VERSION ""

NS_ :

BS_:

BU_: XXX

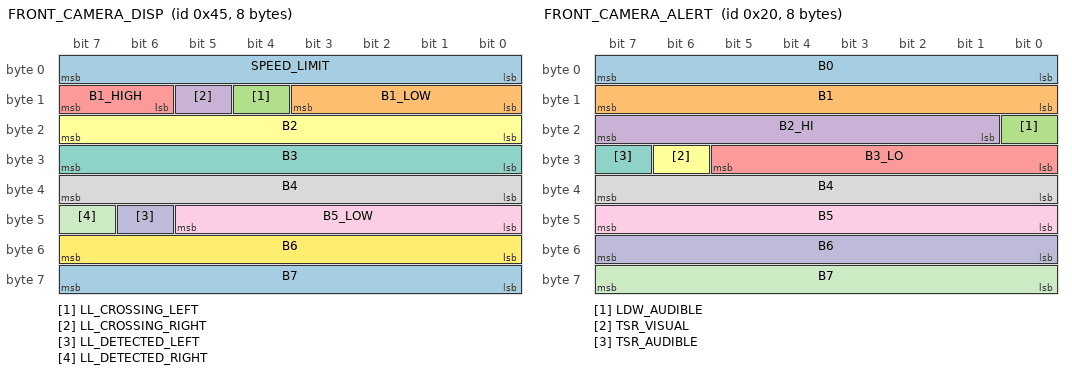
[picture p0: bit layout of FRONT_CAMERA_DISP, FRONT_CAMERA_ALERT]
BO_ 69 FRONT_CAMERA_DISP: 8 XXX
 SG_ SPEED_LIMIT : 0|8@1+ (1,0) [0|255] "mph" XXX
 SG_ B1_LOW : 8|4@1+ (1,0) [0|15] "" XXX
 SG_ LL_CROSSING_LEFT : 12|1@1+ (1,0) [0|1] "" XXX
 SG_ LL_CROSSING_RIGHT : 13|1@1+ (1,0) [0|1] "" XXX
 SG_ B1_HIGH : 14|2@1+ (1,0) [0|3] "" XXX
 SG_ B2 : 16|8@1+ (1,0) [0|255] "" XXX
 SG_ B3 : 24|8@1+ (1,0) [0|255] "" XXX
 SG_ B4 : 32|8@1+ (1,0) [0|255] "" XXX
 SG_ B5_LOW : 40|6@1+ (1,0) [0|63] "" XXX
 SG_ LL_DETECTED_LEFT : 46|1@1+ (1,0) [0|1] "" XXX
 SG_ LL_DETECTED_RIGHT : 47|1@1+ (1,0) [0|1] "" XXX
 SG_ B6 : 48|8@1+ (1,0) [0|255] "" XXX
 SG_ B7 : 56|8@1+ (1,0) [0|255] "" XXX

BO_ 32 FRONT_CAMERA_ALERT: 8 XXX
 SG_ B0 : 0|8@1+ (1,0) [0|255] "" XXX
 SG_ B1 : 8|8@1+ (1,0) [0|255] "" XXX
 SG_ LDW_AUDIBLE : 16|1@1+ (1,0) [0|1] "" XXX
 SG_ B2_HI : 17|7@1+ (1,0) [0|127] "" XXX
 SG_ B3_LO : 24|6@1+ (1,0) [0|63] "" XXX
 SG_ TSR_VISUAL : 30|1@1+ (1,0) [0|1] "" XXX
 SG_ TSR_AUDIBLE : 31|1@1+ (1,0) [0|1] "" XXX
 SG_ B4 : 32|8@1+ (1,0) [0|255] "" XXX
 SG_ B5 : 40|8@1+ (1,0) [0|255] "" XXX
 SG_ B6 : 48|8@1+ (1,0) [0|255] "" XXX
 SG_ B7 : 56|8@1+ (1,0) [0|255] "" XXX

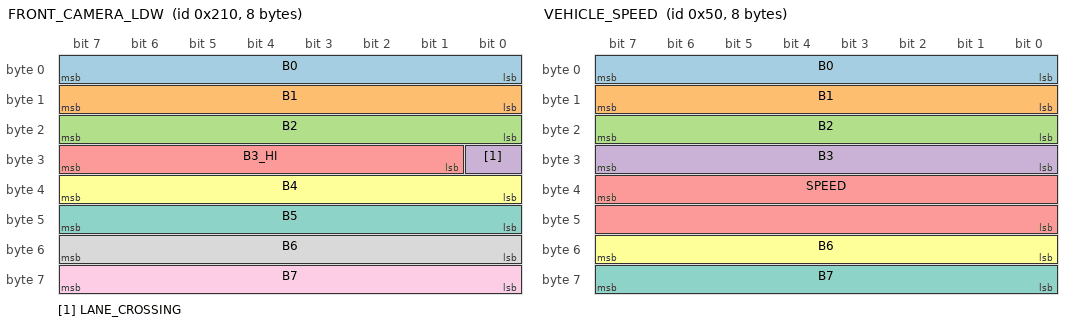
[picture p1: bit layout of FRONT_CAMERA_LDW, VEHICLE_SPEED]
BO_ 528 FRONT_CAMERA_LDW: 8 XXX
 SG_ B0 : 0|8@1+ (1,0) [0|255] "" XXX
 SG_ B1 : 8|8@1+ (1,0) [0|255] "" XXX
 SG_ B2 : 16|8@1+ (1,0) [0|255] "" XXX
 SG_ LANE_CROSSING : 24|1@1+ (1,0) [0|1] "" XXX
 SG_ B3_HI : 25|7@1+ (1,0) [0|127] "" XXX
 SG_ B4 : 32|8@1+ (1,0) [0|255] "" XXX
 SG_ B5 : 40|8@1+ (1,0) [0|255] "" XXX
 SG_ B6 : 48|8@1+ (1,0) [0|255] "" XXX
 SG_ B7 : 56|8@1+ (1,0) [0|255] "" XXX

BO_ 80 VEHICLE_SPEED: 8 XXX
 SG_ B0 : 0|8@1+ (1,0) [0|255] "" XXX
 SG_ B1 : 8|8@1+ (1,0) [0|255] "" XXX
 SG_ B2 : 16|8@1+ (1,0) [0|255] "" XXX
 SG_ B3 : 24|8@1+ (1,0) [0|255] "" XXX
 SG_ SPEED : 39|16@0+ (0.0140625,-460.8) [0|320] "kph" XXX
 SG_ B6 : 48|8@1+ (1,0) [0|255] "" XXX
 SG_ B7 : 56|8@1+ (1,0) [0|255] "" XXX

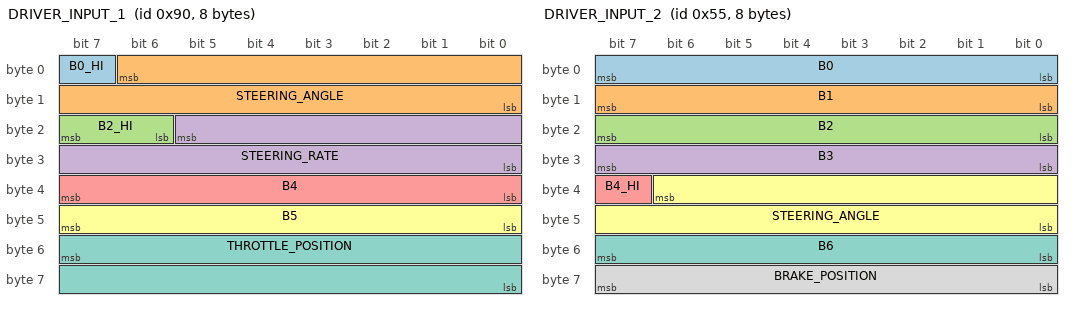
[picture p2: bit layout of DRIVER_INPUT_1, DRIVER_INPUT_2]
BO_ 144 DRIVER_INPUT_1: 8 XXX
 SG_ B0_HI : 7|1@1+ (1,0) [0|1] "" XXX
 SG_ STEERING_ANGLE : 6|15@0- (0.0625,0) [-1024|1024] "deg" XXX
 SG_ B2_HI : 22|2@1+ (1,0) [0|3] "" XXX
 SG_ STEERING_RATE : 21|14@0- (0.5,0) [-4096|4096] "deg/s" XXX
 SG_ B4 : 32|8@1+ (1,0) [0|255] "" XXX
 SG_ B5 : 40|8@1+ (1,0) [0|255] "" XXX
 SG_ THROTTLE_POSITION : 55|16@0+ (0.00390625,-128) [0|100] "%" XXX

BO_ 85 DRIVER_INPUT_2: 8 XXX
 SG_ B0 : 0|8@1+ (1,0) [0|255] "" XXX
 SG_ B1 : 8|8@1+ (1,0) [0|255] "" XXX
 SG_ B2 : 16|8@1+ (1,0) [0|255] "" XXX
 SG_ B3 : 24|8@1+ (1,0) [0|255] "" XXX
 SG_ B4_HI : 39|1@1+ (1,0) [0|1] "" XXX
 SG_ STEERING_ANGLE : 38|15@0- (0.0625,0) [-1024|1024] "deg" XXX
 SG_ B6 : 48|8@1+ (1,0) [0|255] "" XXX
 SG_ BRAKE_POSITION : 56|8@1+ (1,0) [0|255] "" XXX

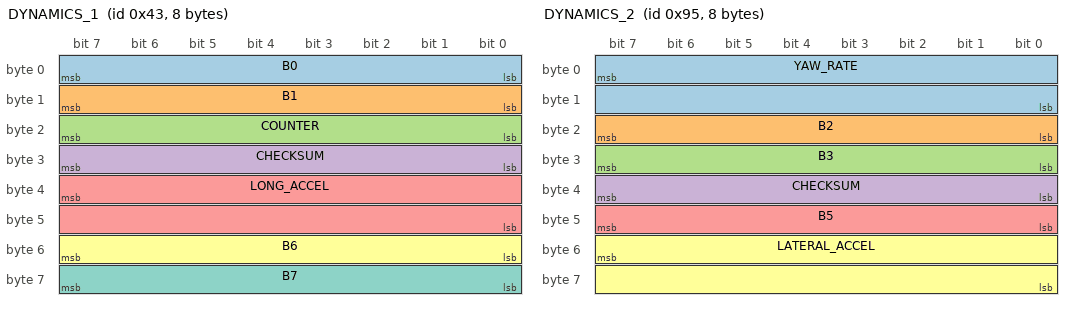
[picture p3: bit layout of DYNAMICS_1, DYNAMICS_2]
BO_ 67 DYNAMICS_1: 8 XXX
 SG_ B0 : 0|8@1+ (1,0) [0|255] "" XXX
 SG_ B1 : 8|8@1+ (1,0) [0|255] "" XXX
 SG_ COUNTER : 16|8@1+ (1,0) [0|255] "" XXX
 SG_ CHECKSUM : 24|8@1+ (1,0) [0|255] "" XXX
 SG_ LONG_ACCEL : 39|16@0- (0.0009765625,0) [-32|32] "m/s2" XXX
 SG_ B6 : 48|8@1+ (1,0) [0|255] "" XXX
 SG_ B7 : 56|8@1+ (1,0) [0|255] "" XXX

BO_ 149 DYNAMICS_2: 8 XXX
 SG_ YAW_RATE : 7|16@0- (1,0) [-32768|32767] "" XXX
 SG_ B2 : 16|8@1+ (1,0) [0|255] "" XXX
 SG_ B3 : 24|8@1+ (1,0) [0|255] "" XXX
 SG_ CHECKSUM : 32|8@1+ (1,0) [0|255] "" XXX
 SG_ B5 : 40|8@1+ (1,0) [0|255] "" XXX
 SG_ LATERAL_ACCEL : 55|16@0- (0.00390625,0) [-128|128] "m/s2" XXX
